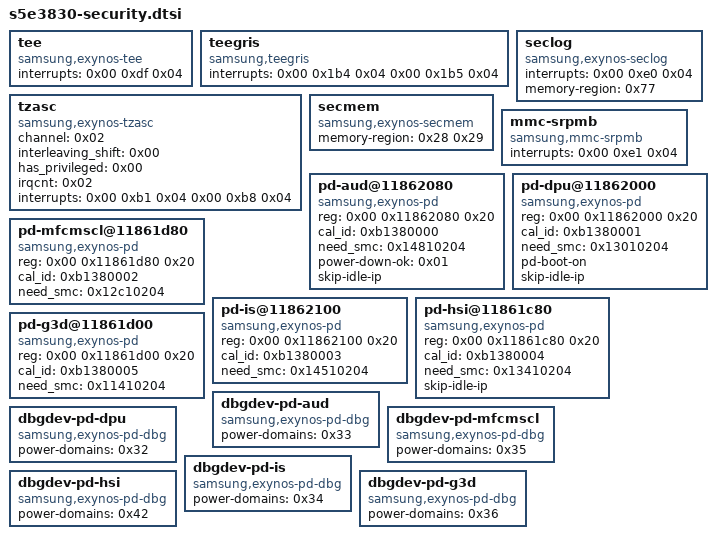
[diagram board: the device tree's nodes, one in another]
/* Samsung Exynos 850 (S5E3830) - TrustZone nodes and power domains */

	tee {
		compatible = "samsung,exynos-tee";
		interrupts = <0x00 0xdf 0x04>;
	};

	teegris {
		compatible = "samsung,teegris";
		interrupts = <0x00 0x1b4 0x04 0x00 0x1b5 0x04>;
	};

	seclog {
		compatible = "samsung,exynos-seclog";
		interrupts = <0x00 0xe0 0x04>;
		memory-region = <0x77>;
	};

	tzasc {
		compatible = "samsung,exynos-tzasc";
		channel = <0x02>;
		interleaving_shift = <0x00>;
		has_privileged = <0x00>;
		irqcnt = <0x02>;
		interrupts = <0x00 0xb1 0x04 0x00 0xb8 0x04>;
	};

	secmem {
		compatible = "samsung,exynos-secmem";
		memory-region = <0x28 0x29>;
	};

	mmc-srpmb {
		compatible = "samsung,mmc-srpmb";
		interrupts = <0x00 0xe1 0x04>;
	};

	pd-aud@11862080 {
		compatible = "samsung,exynos-pd";
		reg = <0x00 0x11862080 0x20>;
		cal_id = <0xb1380000>;
		need_smc = <0x14810204>;
		status = "okay";
		power-down-ok = <0x01>;
		#power-domain-cells = <0x00>;
		skip-idle-ip;
		phandle = <0x33>;
	};

	pd-dpu@11862000 {
		compatible = "samsung,exynos-pd";
		reg = <0x00 0x11862000 0x20>;
		cal_id = <0xb1380001>;
		need_smc = <0x13010204>;
		status = "okay";
		#power-domain-cells = <0x00>;
		pd-boot-on;
		skip-idle-ip;
		phandle = <0x32>;
	};

	pd-mfcmscl@11861d80 {
		compatible = "samsung,exynos-pd";
		reg = <0x00 0x11861d80 0x20>;
		cal_id = <0xb1380002>;
		need_smc = <0x12c10204>;
		status = "okay";
		#power-domain-cells = <0x00>;
		phandle = <0x35>;
	};

	pd-is@11862100 {
		compatible = "samsung,exynos-pd";
		reg = <0x00 0x11862100 0x20>;
		cal_id = <0xb1380003>;
		need_smc = <0x14510204>;
		status = "okay";
		#power-domain-cells = <0x00>;
		phandle = <0x34>;
	};

	pd-hsi@11861c80 {
		compatible = "samsung,exynos-pd";
		reg = <0x00 0x11861c80 0x20>;
		cal_id = <0xb1380004>;
		need_smc = <0x13410204>;
		status = "okay";
		#power-domain-cells = <0x00>;
		skip-idle-ip;
		phandle = <0x42>;
	};

	pd-g3d@11861d00 {
		compatible = "samsung,exynos-pd";
		reg = <0x00 0x11861d00 0x20>;
		cal_id = <0xb1380005>;
		need_smc = <0x11410204>;
		status = "okay";
		#power-domain-cells = <0x00>;
		phandle = <0x36>;
	};

	dbgdev-pd-aud {
		compatible = "samsung,exynos-pd-dbg";
		power-domains = <0x33>;
	};

	dbgdev-pd-dpu {
		compatible = "samsung,exynos-pd-dbg";
		power-domains = <0x32>;
	};

	dbgdev-pd-mfcmscl {
		compatible = "samsung,exynos-pd-dbg";
		power-domains = <0x35>;
	};

	dbgdev-pd-is {
		compatible = "samsung,exynos-pd-dbg";
		power-domains = <0x34>;
	};

	dbgdev-pd-hsi {
		compatible = "samsung,exynos-pd-dbg";
		power-domains = <0x42>;
	};

	dbgdev-pd-g3d {
		compatible = "samsung,exynos-pd-dbg";
		power-domains = <0x36>;
	};
